# RL6845_IP_SVD register map
Vendor: Realtek
Registers are 32-bit, read-write, reset 0x0 unless marked. A register's access mark holds for its fields unless they carry their own. Offsets are from the block's base; [hi:lo] are bit positions; {n}, {i} and the like mark numbered series.

## lp_pmc
Base 0x41008300
0x00 REG_WAK_STATUS0 ro
  [31:0] wak_sta_31_0 — wak evt status. It can't be cleare here, clear at IP side . Bit0: WIFI_FISR_FESR_IRQ Bit1: WIFI_FTSR_MAILBOX_IRQ Bit2: KM4_WAKE_IRQ Bit3: BT_WAKE_HOST Bit4: IPC_KM4 Bit5: IWDG0 Bit6: Timer4 Bit7: Timer5 Bit8: Timer6 Bit9: Timer7 Bit10: pmc_timer0 Bit11: pmc_timer1 Bit12: UART0 Bit13: UART1 Bit14: UART2_BT Bit15: UART_LOG Bit16: GPIOA Bit17: GPIOB Bit18: I2C0 Bit19: I2C1 Bit20: CTOUCH Bit21: RTC Bit22: ADC Bit23: ADC_COMP Bit24: BOR Bit25: PWR_DOWN Bit26: Keyscan Bit27: AON_TIM Bit28: AON_WAKEPIN Bit29: SDIO Bit30~31: Reserved
0x08 REG_WAK_MASK0_NP
  [31:0] wak_km0_imr_31_0 — 1:mask enable for wake NP, this used to wak pmc
0x10 REG_WAK_MASK0_AP
  [31:0] wak_km4_imr_31_0 — 1:mask enable for wake AP
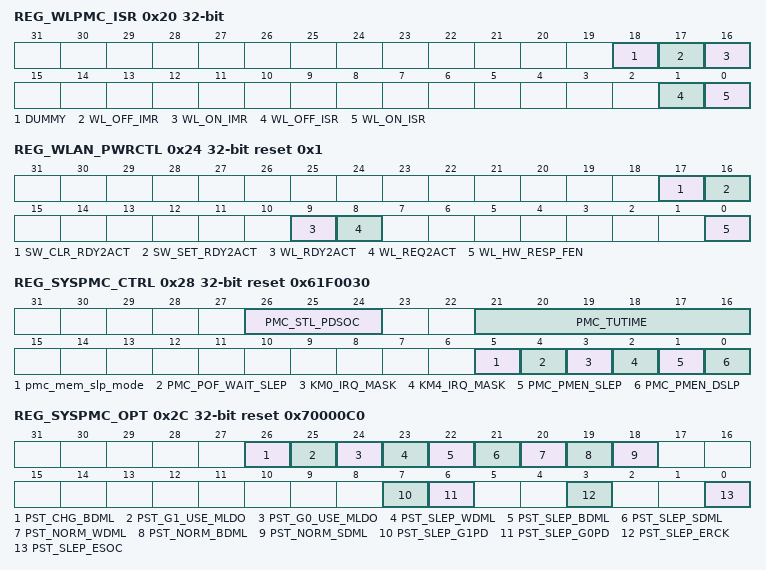
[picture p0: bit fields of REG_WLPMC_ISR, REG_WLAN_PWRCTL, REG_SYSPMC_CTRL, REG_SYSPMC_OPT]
0x20 REG_WLPMC_ISR access per field
  [18] DUMMY rw, [17] WL_OFF_IMR rw, [16] WL_ON_IMR rw, [1] WL_OFF_ISR ro, [0] WL_ON_ISR ro
0x24 REG_WLAN_PWRCTL access per field reset 0x1
  [17] SW_CLR_RDY2ACT rw — System infrom WLAN ready to active
  [16] SW_SET_RDY2ACT rw
  [9] WL_RDY2ACT ro — System infrom WLAN ready to active
  [8] WL_REQ2ACT ro
  [0] WL_HW_RESP_FEN rw — 1: enable HW auto response
0x28 REG_SYSPMC_CTRL reset 0x61F0030
  [26:24] PMC_STL_PDSOC — timer wait for core power power-cut power stable . 000:8us * 2^1 001:8us * 2^2 010:8us * 2^3 // 64us 011:8us * 2^4 100:8us * 2^5 101:8us * 2^6 110:8us * 2^7 // pon default 111:8us * 2^8
  [21:16] PMC_TUTIME — PMC timeunit setting, in cycles of osc4M e.g, default 0x1F, timeunit = 8us
  [5] pmc_mem_slp_mode — Select memory parameter option 1: sleep setting 0: normal setting Note:defautl set to sleep setting to save power when snooze
  [4] PMC_POF_WAIT_SLEP — 1.when SW set pmen_slep or pmen_dslp , hw pmc will wait km0 enter sleep mode , then begin to pof seq 0.Not wait km0 sleep
  [3] KM0_IRQ_MASK — 1.mask all KM0 interrupt 0:release all KM0 interrupt
  [2] KM4_IRQ_MASK — 1.mask all KM4 interrupt 0:release all KM4 interrupt
  [1] PMC_PMEN_SLEP — 1: Request PMC to enter sleep state, auto clear to 0 after PMC finishes
  [0] PMC_PMEN_DSLP — 1: Request PMC to enter deep-sleep state, auto clear to 0 after PMC finishes
0x2C REG_SYSPMC_OPT reset 0x70000C0
  [26] PST_CHG_BDML — normal setting for BT request Core LDO dummy load selection 1: enable dummy load during BT PMC change to sleep mode / normal mode 0: disable dummy load during BT PMC change to sleep mode / normal mode
  [25] PST_G1_USE_MLDO — 1: G1 pad use MLDO 1.8v IO power 0: G1 pad use external power and can't shutdown by pmc
  [24] PST_G0_USE_MLDO — 1: G0 pad use MLDO 1.8v IO power 0: G0 pad use external power and can't shutdown by pmc
  [23] PST_SLEP_WDML — normal setting for WMAC request Core LDO dummy load selection 1: enable dummy load when PMC enter into sleep mode 0: disable dummy load when PMC enter into sleep mode
  [22] PST_SLEP_BDML — normal setting for BT request Core LDO dummy load selection 1: enable dummy load when PMC enter into sleep mode 0: disable dummy load when PMC enter into sleep mode
  [21] PST_SLEP_SDML — normal setting for system request Core LDO dummy load selection 1: enable dummy load when PMC enter into sleep mode 0: disable dummy load when PMC enter into sleep mode
  [20] PST_NORM_WDML — normal setting for WMAC request Core LDO dummy load selection 1: enable dummy load when PMC enter into normal mode 0: disable dummy load when PMC enter into normal mode
  [19] PST_NORM_BDML — normal setting for BT request Core LDO dummy load selection 1: enable dummy load when PMC enter into normal mode 0: disable dummy load when PMC enter into normal mode
  [18] PST_NORM_SDML — normal setting for system request Core LDO dummy load selection 1: enable dummy load when PMC enter into normal mode 0: disable dummy load when PMC enter into normal mode
  [7] PST_SLEP_G1PD — 1: G1 pad used for 1.8v IO power , and will shutdown when LDO3318 off in slep, when dslp , it will always shutoff 0: G1 pad not used as 1.8v IO power
  [6] PST_SLEP_G0PD — 1: G0 pad used for 1.8v IO power , and will shutdown when LDO3318 off in slep,, when dslp , it will always shutoff 0: G0 pad not used as 1.8v IO power
  [3] PST_SLEP_ERCK — 1: Enable lpon clock when PMC enter into sleep mode 0: Gate lpon clock when PMC enter into sleep mode
  [0] PST_SLEP_ESOC — 1: power enable SOC platform when PMC enter into sleep mode (clock-gating) 0: power off SoC domain when PMC enter into sleep mode (power-gating)
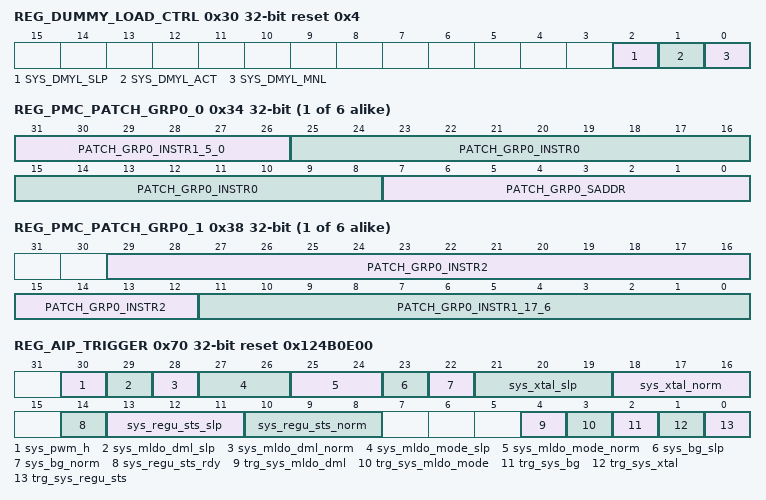
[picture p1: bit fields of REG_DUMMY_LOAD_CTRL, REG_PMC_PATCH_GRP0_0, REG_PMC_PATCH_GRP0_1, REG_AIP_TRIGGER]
0x30 REG_DUMMY_LOAD_CTRL reset 0x4
  [2] SYS_DMYL_SLP — this bit means the dummy load state when KM4 is sleep 0: disable 1: enable
  [1] SYS_DMYL_ACT — this bit means the dummy load state when KM4 is active 0: disable 1: enable
  [0] SYS_DMYL_MNL — system use this bit to switch core ldo dummy load control path manually 0: dummy load control is decided by LS/BT/WL PMC arbitration 1: dummy load control is decided by KM4 sleep state
{0x34+8i} REG_PMC_PATCH_GRP{i}_0 (i=0..5)
  [31:26] PATCH_GRP{i}_INSTR1_5_0 — instruction1 of LSYSON PMC patch group{i},bit[5:0]
  [25:8] PATCH_GRP{i}_INSTR0 — instruction0 of LSYSON PMC patch group{i}
  [7:0] PATCH_GRP{i}_SADDR — Start address of the first instruction of LSYSON PMC patch group{i}
{0x38+8i} REG_PMC_PATCH_GRP{i}_1 (i=0..5)
  [29:12] PATCH_GRP{i}_INSTR2 — instruction2 of LSYSON PMC patch group{i}
  [11:0] PATCH_GRP{i}_INSTR1_17_6 — instruction1 of LSYSON PMC patch group{i},bit[17:6]
0x70 REG_AIP_TRIGGER access per field reset 0x124B0E00
  [30] sys_pwm_h rw — Set pwm in heavy loading by system (SWR current > 200mA) 1:Heavy 0:Light
  [29] sys_mldo_dml_slp rw — mem ldo dummy load slep option 1:dummy load en 0:dummy load disable
  [28] sys_mldo_dml_norm rw — mem ldo dummy load normal option 1:dummy load en 0:dummy load disable
  [27:26] sys_mldo_mode_slp rw — mem ldo mode slep option 00:off 01:sleep 10:normal-0 10:normal-1
  [25:24] sys_mldo_mode_norm rw — mem ldo mode normal option 00:off 01:sleep 10:normal-0 10:normal-1
  [23] sys_bg_slp rw — 0: BG OFF 1: BG ON
  [22] sys_bg_norm rw — 0: BG OFF 1: BG ON
  [21:19] sys_xtal_slp rw — 00: OFF 001: LPS wo 40M 010: LPS with 40M , 011: NORM 100: HP
  [18:16] sys_xtal_norm rw — 00: OFF 001: LPS wo 40M 010: LPS with 40M , 011: NORM 100: HP
  [14] sys_regu_sts_rdy ro — Ready signal for system regu state. Software write trg register and sts different value will lead this bit set to 0 by hardware. When REGU PMC finish the flow, this bit will be set to 1 by hardware.
  [13:11] sys_regu_sts_slp rw — 000: RSVD 001: state1 010: state2 011: state3 100: state4 101: state5 110: state6 111: RSVD
  [10:8] sys_regu_sts_norm rw — 000: RSVD 001: state1 0.7/PC/PFM 010: state2 0.8/PC/PFM 011: state3 0.9/PC/PFM 100: state4 0.9(1.0)/SLP/PFM 101: state5 0.9(1.0)/SLP/PWM 110: state6 0.9(1.0)/NORM/PWM 111: RSVD
  [4] trg_sys_mldo_dml wo
  [3] trg_sys_mldo_mode wo
  [2] trg_sys_bg wo
  [1] trg_sys_xtal wo
  [0] trg_sys_regu_sts wo — write 1 to trigger sys_regu_sts_norm value to take effect
0x74 REG_AIP_OPTION
  [0] osc4m_ign_volt — Options if osc4m can auto require voltage , disable it may speedup reponse time when system nevel goto 0.7v 0. osc4m will send volt areq when osc4m enable or disable 1. osc4m never req volt change , make sure , system voltage will nevel goto 0.7v
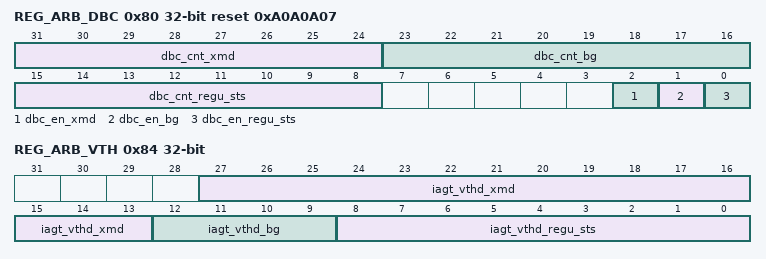
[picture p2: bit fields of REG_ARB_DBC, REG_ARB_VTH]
0x80 REG_ARB_DBC reset 0xA0A0A07
  [31:24] dbc_cnt_xmd — xmd debounce counter , cycle based in OSC4M
  [23:16] dbc_cnt_bg — bg debounce counter , cycle based in OSC4M
  [15:8] dbc_cnt_regu_sts — regu sts debounce counter , cycle based in OSC4M
  [2] dbc_en_xmd — xtal mode arbit debounce enable 0:disable 1:enable
  [1] dbc_en_bg — bg arbit debounce enable 0:disable 1:enable
  [0] dbc_en_regu_sts — regu sts arbit debounce enable 0:disable 1:enable
0x84 REG_ARB_VTH
  [27:13] iagt_vthd_xmd — This field used for xmd arb control.
  [12:9] iagt_vthd_bg — This field used for bg arb control.
  [8:0] iagt_vthd_regu_sts — This field used for regu sts arb control.
